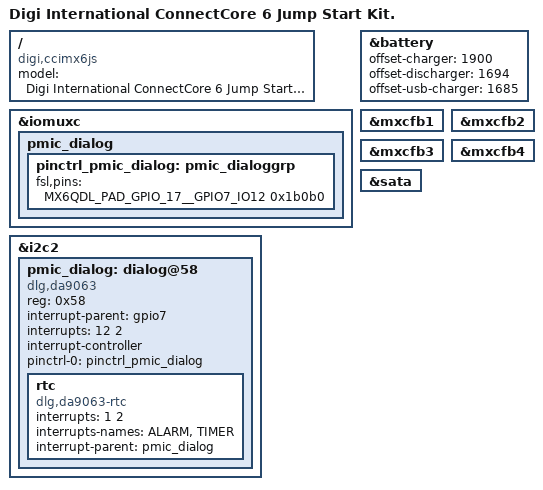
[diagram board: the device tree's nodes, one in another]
/*
 * Copyright 2013 Digi International, Inc.
 * Copyright 2012 Freescale Semiconductor, Inc.
 * Copyright 2011 Linaro Ltd.
 *
 * The code contained herein is licensed under the GNU General Public
 * License. You may obtain a copy of the GNU General Public License
 * Version 2 or later at the following locations:
 *
 * http://www.opensource.org/licenses/gpl-license.html
 * http://www.gnu.org/copyleft/gpl.html
 */

/dts-v1/;

#include "imx6q.dtsi"
#include "imx6-ccimx6qdljs.dtsi"

/ {
	model = "Digi International ConnectCore 6 Jump Start Kit.";
	compatible = "digi,ccimx6js", "fsl,imx6q";
};

&iomuxc {
	pmic_dialog {
		pinctrl_pmic_dialog: pmic_dialoggrp {
			fsl,pins = <
				MX6QDL_PAD_GPIO_17__GPIO7_IO12 0x1b0b0
			>;
		};
	};
};

&i2c2 {
	pmic_dialog: dialog@58 {
		compatible = "dlg,da9063";
		reg = <0x58>;
		interrupt-parent = <&gpio7>;
		interrupts = <12 2>;
		interrupt-controller;
		#interrupt-cells = <1>;
		pinctrl-names = "default";
		pinctrl-0 = <&pinctrl_pmic_dialog>;

		rtc {
			compatible = "dlg,da9063-rtc";
			interrupts = <1 2>;
			interrupts-names = "ALARM" , "TIMER";
			interrupt-parent = <&pmic_dialog>;
		};
	};
};

&battery {
	offset-charger = <1900>;
	offset-discharger = <1694>;
	offset-usb-charger = <1685>;
};

&mxcfb1 {
	status = "okay";
};

&mxcfb2 {
	status = "okay";
};

&mxcfb3 {
	status = "okay";
};

&mxcfb4 {
	status = "okay";
};

&sata {
	status = "okay";
};
